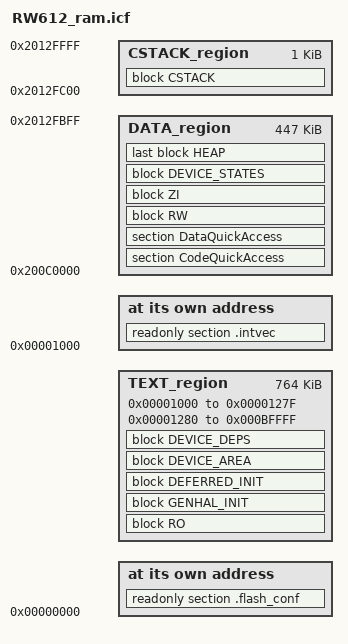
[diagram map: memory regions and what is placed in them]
/*
** ###################################################################
**     Processors:          RW612ETA2I
**                          RW612HNA2I
**                          RW612UKA2I
**
**     Compiler:            IAR ANSI C/C++ Compiler for ARM
**     Reference manual:    RW61X User manual Rev. 0.95, June 2022
**     Version:             rev. 1.0, 2021-03-16
**     Build:               b231201
**
**     Abstract:
**         Linker file for the IAR ANSI C/C++ Compiler for ARM
**
**     Copyright 2016 Freescale Semiconductor, Inc.
**     Copyright 2016-2023 NXP
**     SPDX-License-Identifier: BSD-3-Clause
**
**     http:                 www.nxp.com
**     mail:                 support@nxp.com
**
** ###################################################################
*/

/* Stack and Heap Sizes */
if (isdefinedsymbol(__stack_size__)) {
  define symbol __size_cstack__        = __stack_size__;
} else {
  define symbol __size_cstack__        = 0x0400;
}

if (isdefinedsymbol(__heap_size__)) {
  define symbol __size_heap__          = __heap_size__;
} else {
  define symbol __size_heap__          = 0x0400;
}

define symbol m_interrupts_start               = 0x00001000;
define symbol m_interrupts_end                 = 0x0000127F;

define symbol m_text_start                     = 0x00001280;
define symbol m_text_end                       = 0x000BFFFF;

define symbol m_data_start                     = 0x200C0000;
define symbol m_data_end                       = 0x2012FFFF;

define symbol m_boot_flash_start               = 0x00000000;

define exported symbol __VECTOR_TABLE          = m_interrupts_start;
define exported symbol __VECTOR_RAM            = m_interrupts_start;
define exported symbol __RAM_VECTOR_TABLE_SIZE = 0x0;

define memory mem with size = 4G;

define region TEXT_region             = mem:[from m_interrupts_start to m_interrupts_end]
                                      | mem:[from m_text_start to m_text_end];
define region DATA_region             = mem:[from m_data_start to m_data_end - __size_cstack__];
define region CSTACK_region           = mem:[from m_data_end-__size_cstack__ + 1 to m_data_end];


define block CSTACK    with alignment = 8, size = __size_cstack__   { };
define block HEAP      with alignment = 8, size = __size_heap__     { };
define block RO        { readonly };
define block RW        { readwrite };
define block ZI        { zi };

define block INIT_EARLY        with alignment = 4, fixed order { section .z_init_EARLY?_*, section .z_init_EARLY??_* };
define block INIT_PRE_KERNEL_1 with alignment = 4, fixed order { section .z_init_PRE_KERNEL_1?_*, section .z_init_PRE_KERNEL_1??_* };
define block INIT_PRE_KERNEL_2 with alignment = 4, fixed order { section .z_init_PRE_KERNEL_2?_*, section .z_init_PRE_KERNEL_2??_* };
define block INIT_POST_KERNEL  with alignment = 4, fixed order { section .z_init_POST_KERNEL?_*, section .z_init_POST_KERNEL??_* };
define block INIT_APPLICATION  with alignment = 4, fixed order { section .z_init_APPLICATION?_*, section .z_init_APPLICATION??_* };
define block INIT_SMP          with alignment = 4, fixed order { section .z_init_SMP?_*, section .z_init_SMP??_* };
define block DEFERRED_INIT     with alignment = 4, fixed order { section .z_deferred_init* };

define block GENHAL_INIT       with fixed order { block INIT_EARLY, block INIT_PRE_KERNEL_1, block INIT_PRE_KERNEL_2, block INIT_POST_KERNEL, block INIT_APPLICATION, block INIT_SMP };

define block DEVICE_STATES     with alignment = 4, fixed order { section .z_devstate, section .z_devstate.* };
define block DEVICE_AREA       with alignment = 4, fixed order { section ._device.static.*_?_*, section ._device.static.*_??_* };
define block DEVICE_DEPS       with alignment = 4, fixed order { section .__device_deps_pass2* };

initialize by copy { readwrite, section .textrw, section CodeQuickAccess, section DataQuickAccess, section .z_devstate, section .z_devstate.* };

do not initialize  { section .noinit };

keep{ section .flash_conf };
keep{ block DEFERRED_INIT };
keep{ block GENHAL_INIT };
keep{ block DEVICE_STATES };
keep{ block DEVICE_AREA };
keep{ block DEVICE_DEPS };

place at address mem: m_boot_flash_start    { readonly section .flash_conf };
place at address mem: m_interrupts_start    { readonly section .intvec };
place in TEXT_region                        { block RO };
place in TEXT_region                        { block GENHAL_INIT };
place in TEXT_region                        { block DEFERRED_INIT };
place in TEXT_region                        { block DEVICE_AREA };
place in TEXT_region                        { block DEVICE_DEPS };
place in DATA_region                        { section CodeQuickAccess, section DataQuickAccess };
place in DATA_region                        { block RW };
place in DATA_region                        { block ZI };
place in DATA_region                        { block DEVICE_STATES };
place in DATA_region                        { last block HEAP };
place in CSTACK_region                      { block CSTACK };
